AUTOSAR XML (schema 00052)
package /apd/AdaptiveApplicationSwComponentTypes
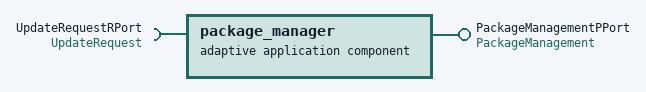
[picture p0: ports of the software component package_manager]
  adaptive application sw component type package_manager
    provide port PackageManagementPPort: provided-interface=PackageManagement
    require port UpdateRequestRPort: required-interface=UpdateRequest
    provide/require port SwPackageCurrentStatusPRPort: provided-required-interface=SwPackageCurrentStatus
    provide/require port SwPackageTransferStatusPRPort: provided-required-interface=SwPackageTransferStatus
package /apd/Executables
  executable package_manager: category=PLATFORM_LEVEL, build-type=BUILD-TYPE-DEBUG, minimum-timer-granularity=1000.0, version=1.0.0
    root sw component prototype package_manager_root: application-type=package_manager
